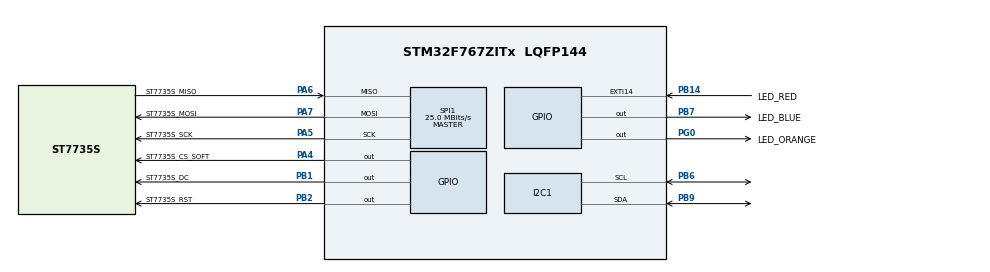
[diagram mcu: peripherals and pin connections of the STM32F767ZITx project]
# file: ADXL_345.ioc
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I2C1.Timing=0x00C0EAFF
Mcu.Family=STM32F7
Mcu.Name=STM32F767ZITx
Mcu.Package=LQFP144
NVIC.PriorityGroup=NVIC_PRIORITYGROUP_4
PA4.GPIO_Label=ST7735S_CS_SOFT
PA4.Signal=GPIO_Output
PA5.GPIO_Label=ST7735S_SCK
PA5.Mode=Full_Duplex_Master
PA5.Signal=SPI1_SCK
PA6.GPIO_Label=ST7735S_MISO
PA6.Mode=Full_Duplex_Master
PA6.Signal=SPI1_MISO
PA7.GPIO_Label=ST7735S_MOSI
PA7.Mode=Full_Duplex_Master
PA7.Signal=SPI1_MOSI
PB1.GPIO_Label=ST7735S_DC
PB1.Signal=GPIO_Output
PB14.GPIO_Label=LED_RED
PB14.Signal=GPXTI14
PB2.GPIO_Label=ST7735S_RST
PB2.Signal=GPIO_Output
PB6.Mode=I2C
PB6.Signal=I2C1_SCL
PB7.GPIO_Label=LED_BLUE
PB7.Signal=GPIO_Output
PB9.Mode=I2C
PB9.Signal=I2C1_SDA
PG0.GPIO_Label=LED_ORANGE
PG0.PinState=GPIO_PIN_RESET
PG0.Signal=GPIO_Output
PH0/OSC_IN.Mode=HSE-External-Oscillator
PH0/OSC_IN.Signal=RCC_OSC_IN
PH1/OSC_OUT.Mode=HSE-External-Oscillator
PH1/OSC_OUT.Signal=RCC_OSC_OUT
ProjectManager.HeapSize=0x200
ProjectManager.StackSize=0x400
ProjectManager.TargetToolchain=STM32CubeIDE
RCC.AHBFreq_Value=100000000
RCC.APB1CLKDivider=RCC_HCLK_DIV2
RCC.APB1Freq_Value=50000000
RCC.APB1TimFreq_Value=100000000
RCC.APB2CLKDivider=RCC_HCLK_DIV2
RCC.APB2Freq_Value=50000000
RCC.APB2TimFreq_Value=100000000
RCC.CortexFreq_Value=100000000
RCC.HCLKFreq_Value=100000000
RCC.HSE_VALUE=25000000
RCC.HSI_VALUE=16000000
RCC.LSE_VALUE=32768
RCC.PLLM=12
RCC.PLLN=96
RCC.PLLSourceVirtual=RCC_PLLSOURCE_HSE
RCC.SYSCLKFreq_VALUE=100000000
RCC.SYSCLKSource=RCC_SYSCLKSOURCE_PLLCLK
RCC.USBFreq_Value=100000000
RCC.VCOOutputFreq_Value=200000000
SPI1.CalculateBaudRate=25.0 MBits/s
SPI1.Direction=SPI_DIRECTION_2LINES
SPI1.Mode=SPI_MODE_MASTER
SPI1.VirtualType=VM_MASTER
board=custom

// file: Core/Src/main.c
/* USER CODE BEGIN Header */
/**
  ******************************************************************************
  * @file           : main.c
  * @brief          : Main program body
  ******************************************************************************
  * @attention
  *
  * Copyright (c) 2024 STMicroelectronics.
  * All rights reserved.
  *
  * This software is licensed under terms that can be found in the LICENSE file
  * in the root directory of this software component.
  * If no LICENSE file comes with this software, it is provided AS-IS.
  *
  ******************************************************************************
  */
/* USER CODE END Header */
#include "main.h"

int main(void)
{

  /* USER CODE BEGIN 1 */
	bool isADXLInit = false;
  /* USER CODE END 1 */

  /* MCU Configuration--------------------------------------------------------*/

  /* Reset of all peripherals, Initializes the Flash interface and the Systick. */
  HAL_Init();

  /* Configure the system clock */
  SystemClock_Config();

  /* Initialize all configured peripherals */
  MX_GPIO_Init();
  MX_I2C1_Init();
  MX_SPI1_Init();
  /* USER CODE BEGIN 2 */

  if(ADXL345_Init()==ADXL345_INIT_OK)
  {
	  isADXLInit = true;
  }
  /* USER CODE END 2 */

  /* Infinite loop */
  /* USER CODE BEGIN WHILE */
  while (1)
  {
	   if(isADXLInit == true)
	  {
		  if(CalculateDisplacement()==true)
		  {
			  HAL_GPIO_TogglePin(LED_ORANGE_GPIO_Port, LED_ORANGE_Pin);
	  	  	  HAL_Delay(100);
		  }
	  }

    /* USER CODE END WHILE */

  }
}
